# SAM9X60D1G_SOM register map
Vendor: Microchip Technology; Series: SAM9X6; File version: 0
Registers are 32-bit, read-write, reset 0x0 unless marked. A register's access mark holds for its fields unless they carry their own. Offsets are from the block's base; [hi:lo] are bit positions; {n}, {i} and the like mark numbered series.

## PIOA — Parallel Input/Output Controller
Base 0xFFFFF400; register names take the prefix PIO_
Same registers: PIOB 0xFFFFF600, PIOC 0xFFFFF800, PIOD 0xFFFFFA00
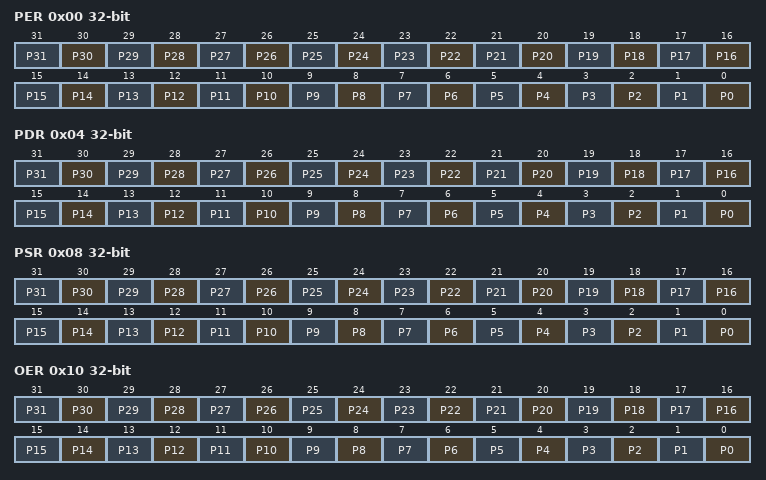
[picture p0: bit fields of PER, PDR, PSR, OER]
0x00 PER wo — PIO Enable Register
  [n] P{n} (n=0..31) — PIO Enable
0x04 PDR wo — PIO Disable Register
  [n] P{n} (n=0..31) — PIO Disable
0x08 PSR ro — PIO Status Register
  [n] P{n} (n=0..31) — PIO Status
0x10 OER wo — Output Enable Register
  [n] P{n} (n=0..31) — Output Enable
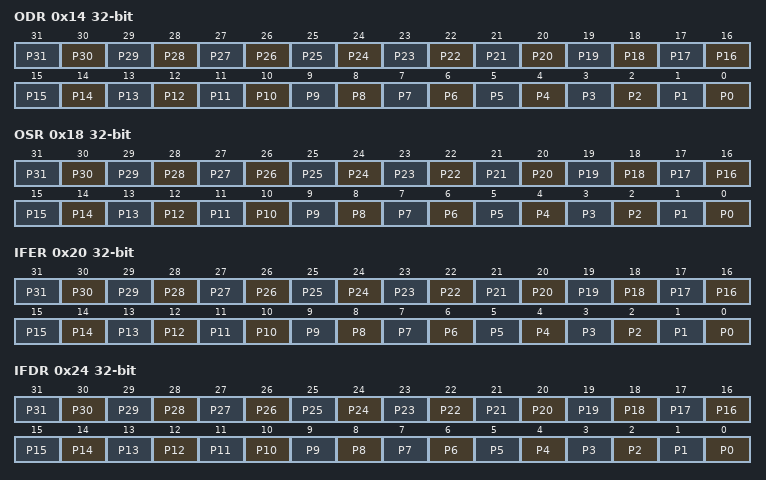
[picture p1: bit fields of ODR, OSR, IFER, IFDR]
0x14 ODR wo — Output Disable Register
  [n] P{n} (n=0..31) — Output Disable
0x18 OSR ro — Output Status Register
  [n] P{n} (n=0..31) — Output Status
0x20 IFER wo — Glitch Input Filter Enable Register
  [n] P{n} (n=0..31) — Input Filter Enable
0x24 IFDR wo — Glitch Input Filter Disable Register
  [n] P{n} (n=0..31) — Input Filter Disable
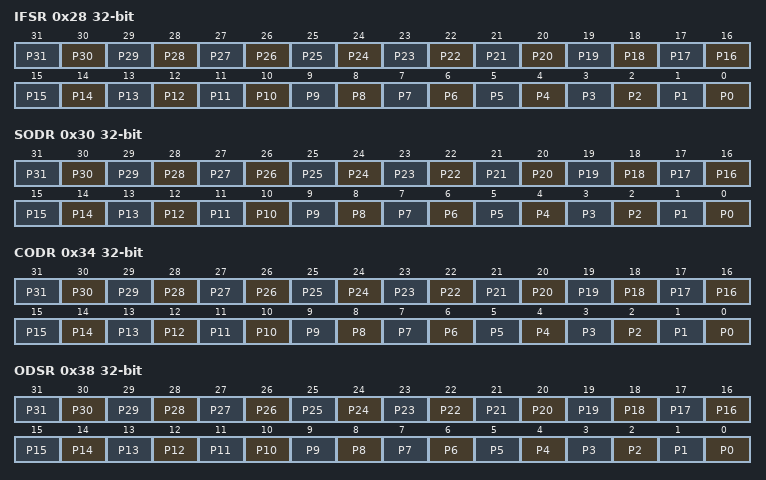
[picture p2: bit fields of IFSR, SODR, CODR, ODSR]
0x28 IFSR ro — Glitch Input Filter Status Register
  [n] P{n} (n=0..31) — Input Filter Status
0x30 SODR wo — Set Output Data Register
  [n] P{n} (n=0..31) — Set Output Data
0x34 CODR wo — Clear Output Data Register
  [n] P{n} (n=0..31) — Clear Output Data
0x38 ODSR — Output Data Status Register
  [n] P{n} (n=0..31) — Output Data Status
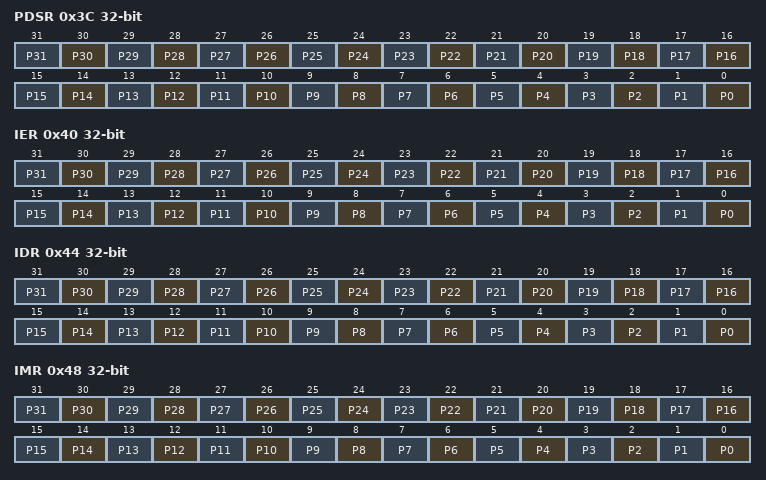
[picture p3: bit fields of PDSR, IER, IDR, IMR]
0x3C PDSR ro — Pin Data Status Register
  [n] P{n} (n=0..31) — Output Data Status
0x40 IER wo — Interrupt Enable Register
  [n] P{n} (n=0..31) — Input Change Interrupt Enable
0x44 IDR wo — Interrupt Disable Register
  [n] P{n} (n=0..31) — Input Change Interrupt Disable
0x48 IMR ro — Interrupt Mask Register
  [n] P{n} (n=0..31) — Input Change Interrupt Mask
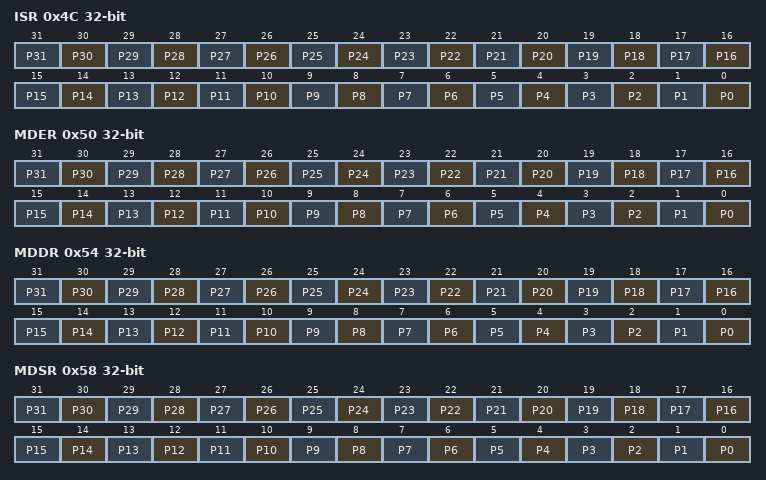
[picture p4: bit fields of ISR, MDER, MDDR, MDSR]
0x4C ISR ro — Interrupt Status Register
  [n] P{n} (n=0..31) — Input Change Interrupt Status
0x50 MDER wo — Multi-driver Enable Register
  [n] P{n} (n=0..31) — Multi-drive Enable
0x54 MDDR wo — Multi-driver Disable Register
  [n] P{n} (n=0..31) — Multi-drive Disable
0x58 MDSR ro — Multi-driver Status Register
  [n] P{n} (n=0..31) — Multi-drive Status
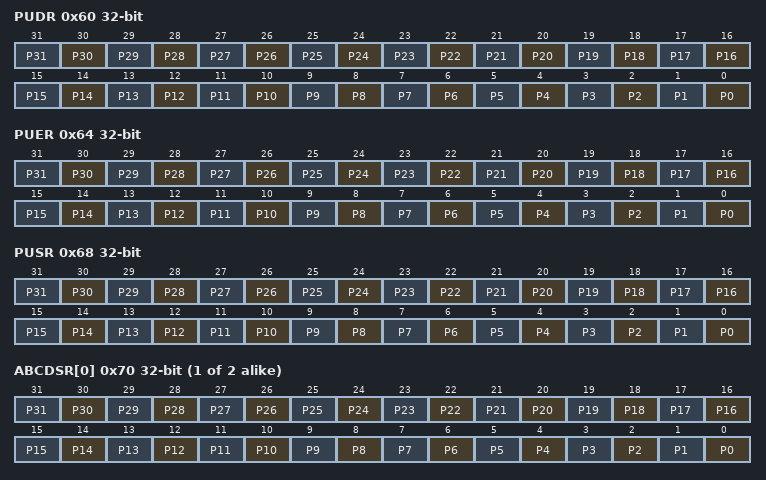
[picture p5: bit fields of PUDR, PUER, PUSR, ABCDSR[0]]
0x60 PUDR wo — Pull-Up Disable Register
  [n] P{n} (n=0..31) — Pull-Up Disable
0x64 PUER wo — Pull-Up Enable Register
  [n] P{n} (n=0..31) — Pull-Up Enable
0x68 PUSR ro — Pad Pull-Up Status Register
  [n] P{n} (n=0..31) — Pull-Up Status
{0x70+4i} ABCDSR[{i}] (i=0..1) — Peripheral ABCD Select Register
  [n] P{n} (n=0..31) — Peripheral Select
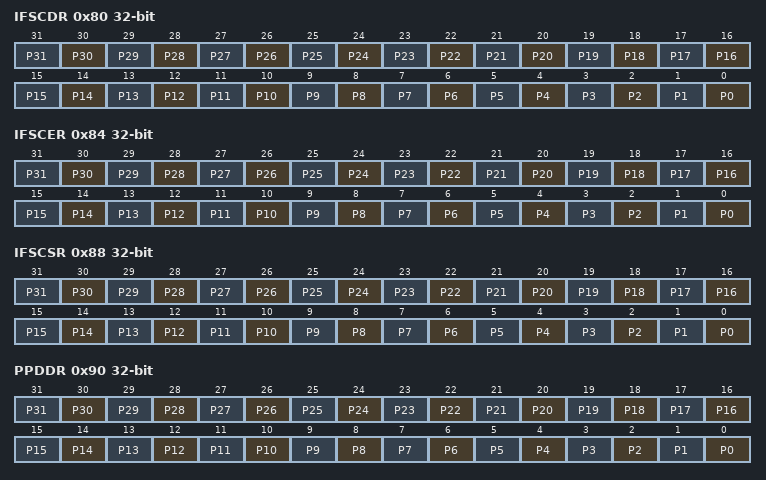
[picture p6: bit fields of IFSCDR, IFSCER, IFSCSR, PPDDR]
0x80 IFSCDR wo — Input Filter Slow Clock Disable Register
  [n] P{n} (n=0..31) — Peripheral Clock Glitch Filtering Select
0x84 IFSCER wo — Input Filter Slow Clock Enable Register
  [n] P{n} (n=0..31) — Slow Clock Debouncing Filtering Select
0x88 IFSCSR ro — Input Filter Slow Clock Status Register
  [n] P{n} (n=0..31) — Glitch or Debouncing Filter Selection Status
0x8C SCDR — Slow Clock Divider Debouncing Register
  [13:0] DIV — Slow Clock Divider Selection for Debouncing
0x90 PPDDR wo — Pad Pull-Down Disable Register
  [n] P{n} (n=0..31) — Pull-Down Disable
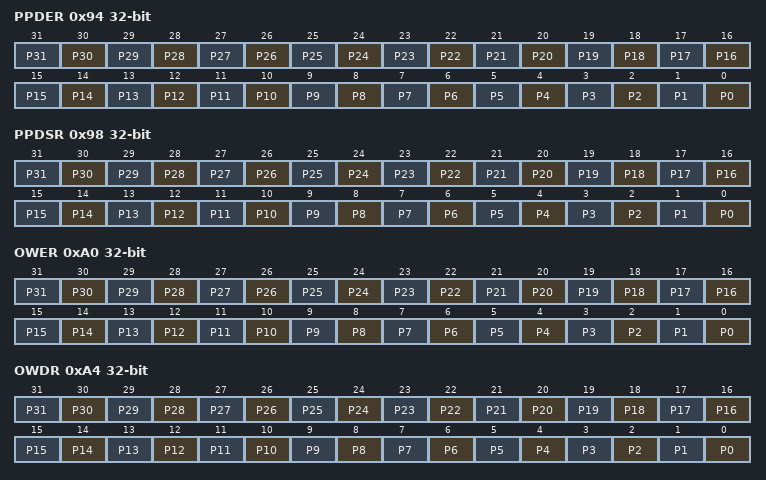
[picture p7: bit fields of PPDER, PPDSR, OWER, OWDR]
0x94 PPDER wo — Pad Pull-Down Enable Register
  [n] P{n} (n=0..31) — Pull-Down Enable
0x98 PPDSR ro — Pad Pull-Down Status Register
  [n] P{n} (n=0..31) — Pull-Down Status
0xA0 OWER wo — Output Write Enable
  [n] P{n} (n=0..31) — Output Write Enable
0xA4 OWDR wo — Output Write Disable
  [n] P{n} (n=0..31) — Output Write Disable
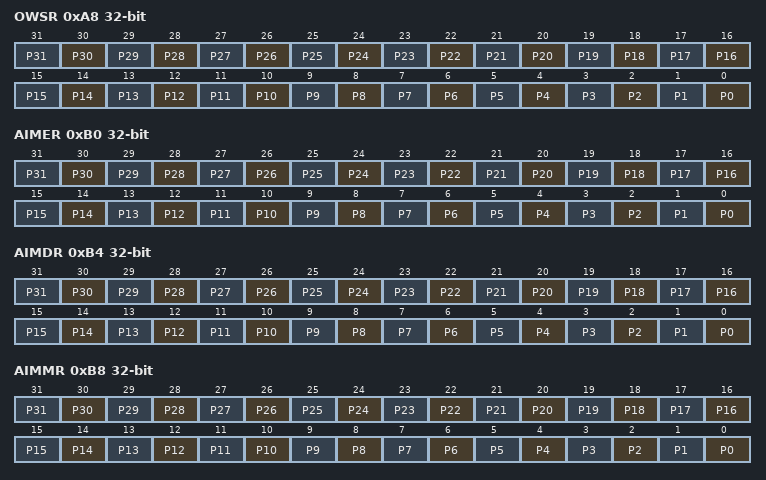
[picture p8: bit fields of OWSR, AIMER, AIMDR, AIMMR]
0xA8 OWSR ro — Output Write Status Register
  [n] P{n} (n=0..31) — Output Write Status
0xB0 AIMER wo — Additional Interrupt Modes Enable Register
  [n] P{n} (n=0..31) — Additional Interrupt Modes Enable
0xB4 AIMDR wo — Additional Interrupt Modes Disable Register
  [n] P{n} (n=0..31) — Additional Interrupt Modes Disable
0xB8 AIMMR ro — Additional Interrupt Modes Mask Register
  [n] P{n} (n=0..31) — IO Line Index
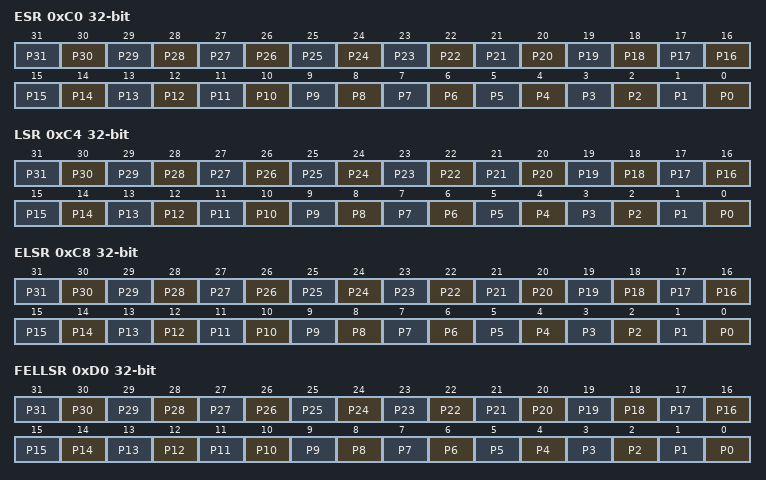
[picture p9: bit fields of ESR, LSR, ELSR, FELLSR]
0xC0 ESR wo — Edge Select Register
  [n] P{n} (n=0..31) — Edge Interrupt Selection
0xC4 LSR wo — Level Select Register
  [n] P{n} (n=0..31) — Level Interrupt Selection
0xC8 ELSR ro — Edge/Level Status Register
  [n] P{n} (n=0..31) — Edge/Level Interrupt Source Selection
0xD0 FELLSR wo — Falling Edge/Low-Level Select Register
  [n] P{n} (n=0..31) — Falling Edge/Low-Level Interrupt Selection
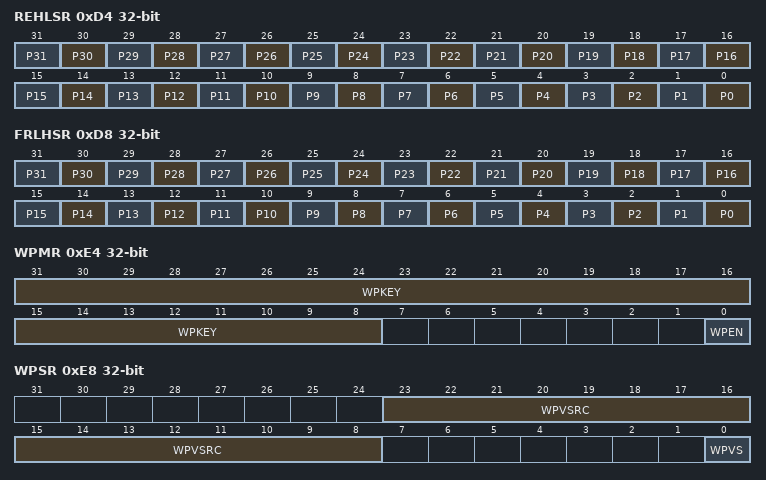
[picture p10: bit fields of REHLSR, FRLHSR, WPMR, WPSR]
0xD4 REHLSR wo — Rising Edge/High-Level Select Register
  [n] P{n} (n=0..31) — Rising Edge/High-Level Interrupt Selection
0xD8 FRLHSR ro — Fall/Rise - Low/High Status Register
  [n] P{n} (n=0..31) — Edge/Level Interrupt Source Selection
0xE4 WPMR — Write Protection Mode Register
  [31:8] WPKEY — Write Protection Key
    0x50494F=PASSWD (Writing any other value in this field aborts the write operation of the WPEN bit. Always reads as 0.)
  [0] WPEN — Write Protection Enable
0xE8 WPSR ro — Write Protection Status Register
  [23:8] WPVSRC — Write Protection Violation Source
  [0] WPVS — Write Protection Violation Status
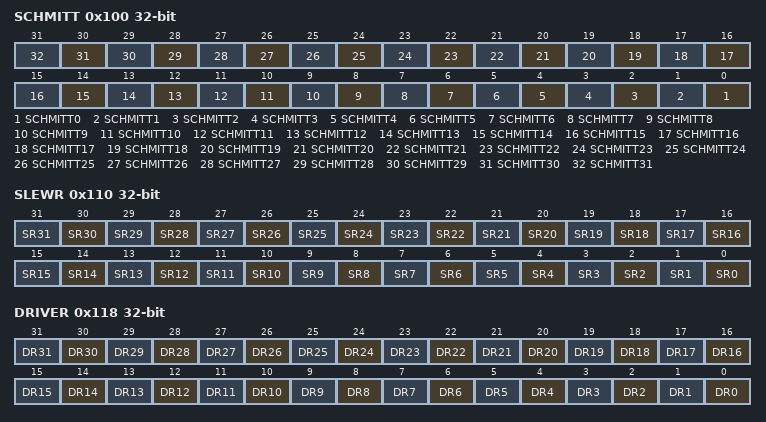
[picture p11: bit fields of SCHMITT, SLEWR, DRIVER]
0x100 SCHMITT — Schmitt Trigger Register
  [n] SCHMITT{n} (n=0..31) — Schmitt Trigger Control
0x110 SLEWR — I/O Slewrate Control Register
  [all] fields
    0=DISABLED (No slewrate control.); 1=ENABLED (Slewrate controlled.)
  [n] SR{n} (n=0..31) — Slewrate Control for IO line {n}
0x118 DRIVER — I/O Drive Register
  [all] fields
    0=LOW (Lowest drive); 1=HIGH (Highest drive)
  [n] DR{n} (n=0..31) — Drive of I/O Line {n}
